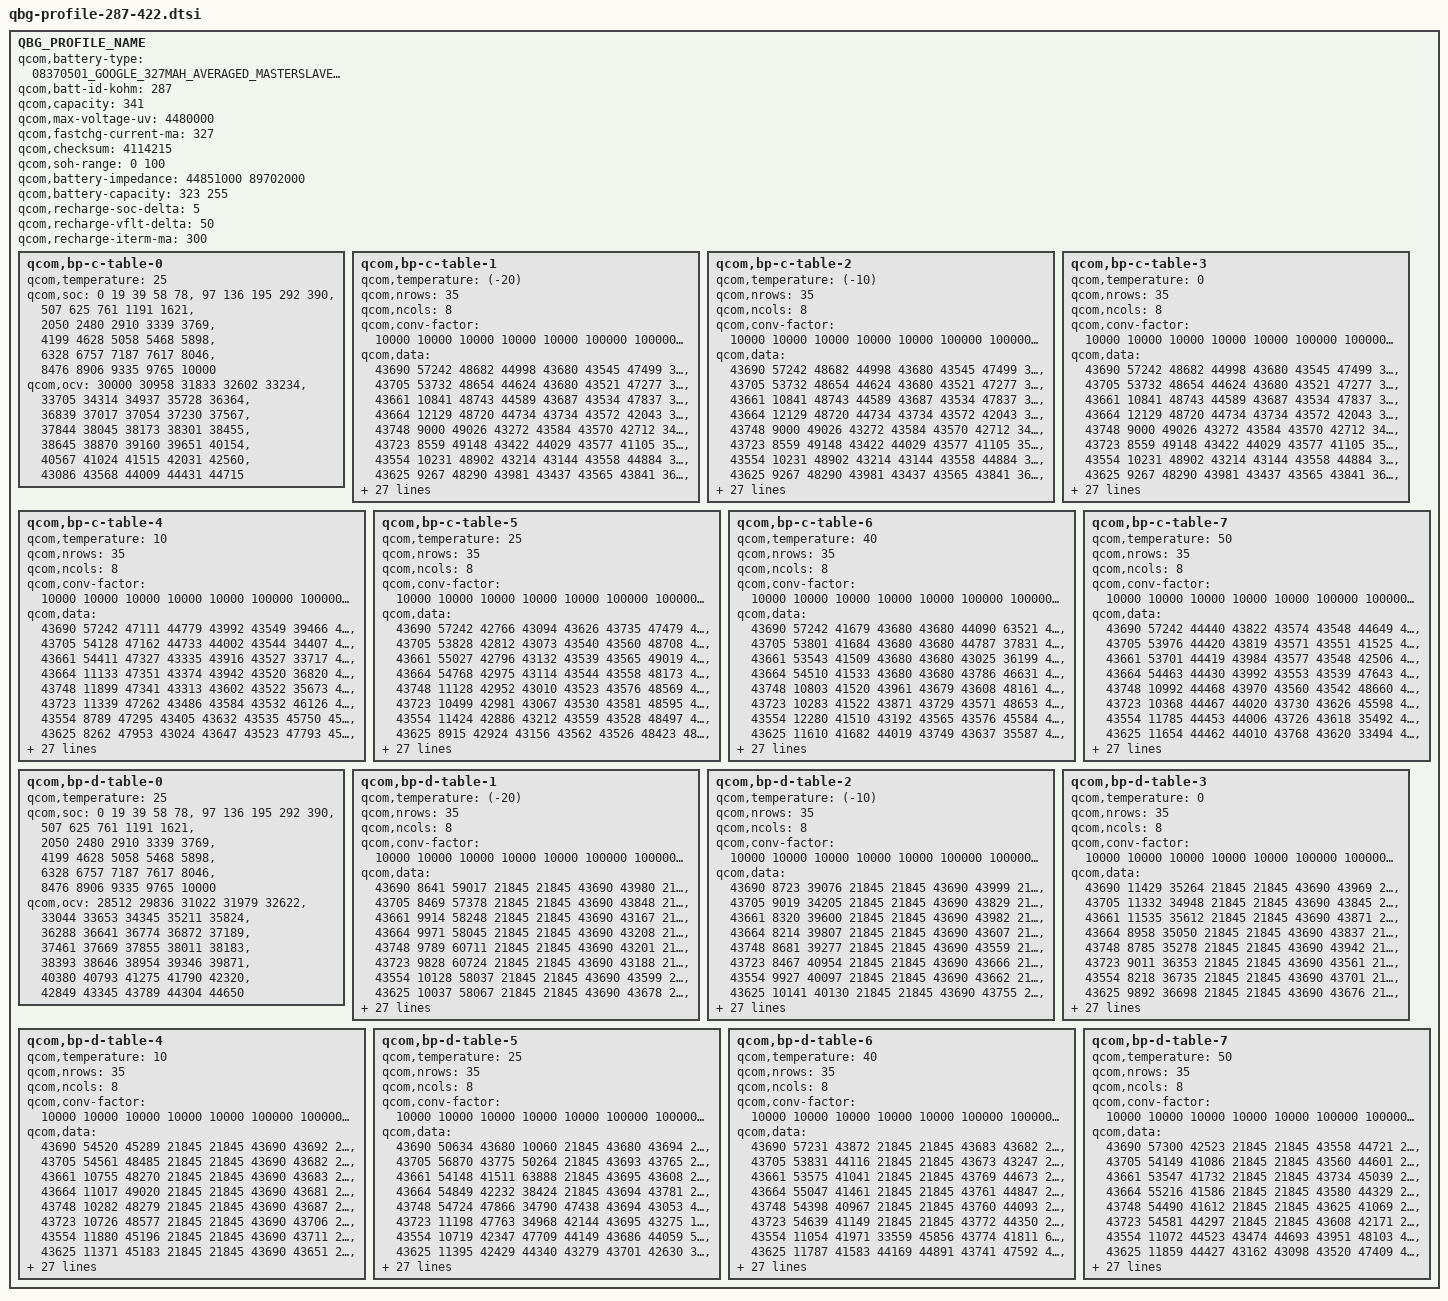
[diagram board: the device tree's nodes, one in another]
/*QBG Profiling Rev. 2.8*/

QBG_PROFILE_NAME {
	qcom,battery-type = "08370501_GOOGLE_327MAH_AVERAGED_MASTERSLAVE_MAR23RD2026";
	qcom,batt-id-kohm = <287>;
	qcom,capacity = <341>;
	qcom,max-voltage-uv = <4480000>;
	qcom,fastchg-current-ma = <327>;
	qcom,checksum = <4114215>; /*@5, 0.005V, 4% */
	qcom,soh-range = <0 100>;
	qcom,battery-impedance = <44851000 89702000>; /*Nominal_Impedance in 10nohm @ SOC 50% 25C* 0:fresh cell, 1: aged cell*/
	qcom,battery-capacity = <323 255>; /*Nominal_Capacity in mAh. 0: fresh cell, 1:aged cell*/ 
	qcom,recharge-soc-delta =<5>; /*SOC delta (in percent) dropped from EOC SOC to enable recharge*/ 
	qcom,recharge-vflt-delta =<50>; /*vfloat delta (in mV) dropped from regular vfloat in recharge*/ 
	qcom,recharge-iterm-ma = <300>; /*termination current (in mA) in recharge*/ 

	qcom,bp-c-table-0 {
		qcom,temperature = <25>;
		qcom,soc = <    0    19    39    58    78>,
			<   97   136   195   292   390>,
			<  507   625   761  1191  1621>,
			< 2050  2480  2910  3339  3769>,
			< 4199  4628  5058  5468  5898>,
			< 6328  6757  7187  7617  8046>,
			< 8476  8906  9335  9765 10000>;
		qcom,ocv = <30000 30958 31833 32602 33234>,
			<33705 34314 34937 35728 36364>,
			<36839 37017 37054 37230 37567>,
			<37844 38045 38173 38301 38455>,
			<38645 38870 39160 39651 40154>,
			<40567 41024 41515 42031 42560>,
			<43086 43568 44009 44431 44715>;
	};
	qcom,bp-c-table-1 {
		qcom,temperature = <(-20)>;
		qcom,nrows = <35>;
		qcom,ncols = <8>;
		qcom,conv-factor = <10000 10000 10000 10000 10000 100000 100000 10000>;
		qcom,data = <43690 57242 48682 44998 43680 43545 47499 34993>,
			<43705 53732 48654 44624 43680 43521 47277 34964>,
			<43661 10841 48743 44589 43687 43534 47837 35035>,
			<43664 12129 48720 44734 43734 43572 42043 34821>,
			<43748  9000 49026 43272 43584 43570 42712 34911>,
			<43723  8559 49148 43422 44029 43577 41105 35220>,
			<43554 10231 48902 43214 43144 43558 44884 35169>,
			<43625  9267 48290 43981 43437 43565 43841 36606>,
			<43918 15018 48273 43770 43281 43578 43938 36571>,
			<43820 15047 48276 43771 43363 43579 43950 36603>,
			<43857 14861 48346 43526 43464 43570 44004 36482>,
			<43227 14961 48172 43625 43313 43555 44024 36458>,
			<43091 15247 48141 43632 43301 43556 43974 36774>,
			<44557 14546 48613 43852 43487 43558 44737 36327>,
			<44287 14642 48447 44503 44030 43556 35351 32831>,
			<41640 16081 48567 41600 43883 43582 45521 32994>,
			<41754 16303 48203 41530 43232 43583 48342 32925>,
			<41460 16351 48562 41550 43056 43559 48737 33163>,
			<42913 16216 48588 41956 43127 43567 48696 34498>,
			<42003 15423 48401 41750 43454 43733 48825 34671>,
			<47821 15814 45708 41103 43496 43731 47358 34192>,
			<47294 13014 45676 41175 43482 43736 42295 39448>,
			<47464 13153 45977 41013 43293 43718 41048 39076>,
			<49142 12680 45220 41024 44687 43724 41508 39254>,
			<48544 13832 45068 41410 44545 43720 44530 40138>,
			<45586 13460 45565 41287 45041 43764 44284 37786>,
			<45263 13660 46845 42714 44232 43761 45053 38422>,
			<46777  2921 47061 42571 41645 43760 44737 60365>,
			<46955  2307 46182 42938 41022 43762 43463 60831>,
			<46532  3892 35483 42883 42217 43763 43036 58588>,
			<35766  3376 35782 42970 47539 43761 43165 65017>,
			<34912   979 34848 42203 46029 43767 43858 51436>,
			<36573   389 35265 42099 36404 43761 43881 55353>,
			<35983  1657 36510 42577 34765 43762 44021 55119>,
			<36282  1890 36769 41551 33519 43732 43590 54155>;
	};
	qcom,bp-c-table-2 {
		qcom,temperature = <(-10)>;
		qcom,nrows = <35>;
		qcom,ncols = <8>;
		qcom,conv-factor = <10000 10000 10000 10000 10000 100000 100000 10000>;
		qcom,data = <43690 57242 48682 44998 43680 43545 47499 34993>,
			<43705 53732 48654 44624 43680 43521 47277 34964>,
			<43661 10841 48743 44589 43687 43534 47837 35035>,
			<43664 12129 48720 44734 43734 43572 42043 34821>,
			<43748  9000 49026 43272 43584 43570 42712 34911>,
			<43723  8559 49148 43422 44029 43577 41105 35220>,
			<43554 10231 48902 43214 43144 43558 44884 35169>,
			<43625  9267 48290 43981 43437 43565 43841 36606>,
			<43918 15018 48273 43770 43281 43578 43938 36571>,
			<43820 15047 48276 43771 43363 43579 43950 36603>,
			<43857 14861 48346 43526 43464 43570 44004 36482>,
			<43227 14961 48172 43625 43313 43555 44024 36458>,
			<43091 15247 48141 43632 43301 43556 43974 36774>,
			<44557 14546 48613 43852 43487 43558 44737 36327>,
			<44287 14642 48447 44503 44030 43556 35351 32831>,
			<41640 16081 48567 41600 43883 43582 45521 32994>,
			<41754 16303 48203 41530 43232 43583 48342 32925>,
			<41460 16351 48562 41550 43056 43559 48737 33163>,
			<42913 16216 48588 41956 43127 43567 48696 34498>,
			<42003 15423 48401 41750 43454 43733 48825 34671>,
			<47821 15814 45708 41103 43496 43731 47358 34192>,
			<47294 13014 45676 41175 43482 43736 42295 39448>,
			<47464 13153 45977 41013 43293 43718 41048 39076>,
			<49142 12680 45220 41024 44687 43724 41508 39254>,
			<48544 13832 45068 41410 44545 43720 44530 40138>,
			<45586 13460 45565 41287 45041 43764 44284 37786>,
			<45263 13660 46845 42714 44232 43761 45053 38422>,
			<46777  2921 47061 42571 41645 43760 44737 60365>,
			<46955  2307 46182 42938 41022 43762 43463 60831>,
			<46532  3892 35483 42883 42217 43763 43036 58588>,
			<35766  3376 35782 42970 47539 43761 43165 65017>,
			<34912   979 34848 42203 46029 43767 43858 51436>,
			<36573   389 35265 42099 36404 43761 43881 55353>,
			<35983  1657 36510 42577 34765 43762 44021 55119>,
			<36282  1890 36769 41551 33519 43732 43590 54155>;
	};
	qcom,bp-c-table-3 {
		qcom,temperature = <0>;
		qcom,nrows = <35>;
		qcom,ncols = <8>;
		qcom,conv-factor = <10000 10000 10000 10000 10000 100000 100000 10000>;
		qcom,data = <43690 57242 48682 44998 43680 43545 47499 34993>,
			<43705 53732 48654 44624 43680 43521 47277 34964>,
			<43661 10841 48743 44589 43687 43534 47837 35035>,
			<43664 12129 48720 44734 43734 43572 42043 34821>,
			<43748  9000 49026 43272 43584 43570 42712 34911>,
			<43723  8559 49148 43422 44029 43577 41105 35220>,
			<43554 10231 48902 43214 43144 43558 44884 35169>,
			<43625  9267 48290 43981 43437 43565 43841 36606>,
			<43918 15018 48273 43770 43281 43578 43938 36571>,
			<43820 15047 48276 43771 43363 43579 43950 36603>,
			<43857 14861 48346 43526 43464 43570 44004 36482>,
			<43227 14961 48172 43625 43313 43555 44024 36458>,
			<43091 15247 48141 43632 43301 43556 43974 36774>,
			<44557 14546 48613 43852 43487 43558 44737 36327>,
			<44287 14642 48447 44503 44030 43556 35351 32831>,
			<41640 16081 48567 41600 43883 43582 45521 32994>,
			<41754 16303 48203 41530 43232 43583 48342 32925>,
			<41460 16351 48562 41550 43056 43559 48737 33163>,
			<42913 16216 48588 41956 43127 43567 48696 34498>,
			<42003 15423 48401 41750 43454 43733 48825 34671>,
			<47821 15814 45708 41103 43496 43731 47358 34192>,
			<47294 13014 45676 41175 43482 43736 42295 39448>,
			<47464 13153 45977 41013 43293 43718 41048 39076>,
			<49142 12680 45220 41024 44687 43724 41508 39254>,
			<48544 13832 45068 41410 44545 43720 44530 40138>,
			<45586 13460 45565 41287 45041 43764 44284 37786>,
			<45263 13660 46845 42714 44232 43761 45053 38422>,
			<46777  2921 47061 42571 41645 43760 44737 60365>,
			<46955  2307 46182 42938 41022 43762 43463 60831>,
			<46532  3892 35483 42883 42217 43763 43036 58588>,
			<35766  3376 35782 42970 47539 43761 43165 65017>,
			<34912   979 34848 42203 46029 43767 43858 51436>,
			<36573   389 35265 42099 36404 43761 43881 55353>,
			<35983  1657 36510 42577 34765 43762 44021 55119>,
			<36282  1890 36769 41551 33519 43732 43590 54155>;
	};
	qcom,bp-c-table-4 {
		qcom,temperature = <10>;
		qcom,nrows = <35>;
		qcom,ncols = <8>;
		qcom,conv-factor = <10000 10000 10000 10000 10000 100000 100000 10000>;
		qcom,data = <43690 57242 47111 44779 43992 43549 39466 46997>,
			<43705 54128 47162 44733 44002 43544 34407 46663>,
			<43661 54411 47327 43335 43916 43527 33717 46640>,
			<43664 11133 47351 43374 43942 43520 36820 46819>,
			<43748 11899 47341 43313 43602 43522 35673 45392>,
			<43723 11339 47262 43486 43584 43532 46126 45316>,
			<43554  8789 47295 43405 43632 43535 45750 45450>,
			<43625  8262 47953 43024 43647 43523 47793 45273>,
			<43918 10027 47267 43198 43955 43542 44035 45853>,
			<43820  9718 47994 43633 43161 43585 43798 46072>,
			<43857 15090 47878 43947 43863 43589 43843 45993>,
			<43227 14896 47881 43610 43181 43584 43850 45666>,
			<43091 14950 47921 44004 43778 43587 43314 45598>,
			<44557 15212 47925 43484 43541 43533 46657 45909>,
			<44287 14783 48036 44643 43598 43572 36433 45119>,
			<41640 16039 47841 45028 43938 43521 36309 45231>,
			<41754 15877 42265 44851 43928 43536 36643 45877>,
			<41460 16310 42255 44831 44023 43549 35212 45925>,
			<42913 16179 42269 44923 43818 43526 35806 45215>,
			<42003 15515 42305 44194 43787 43534 35253 45160>,
			<47821 15442 47781 44267 43806 43572 36065 45536>,
			<47294 12989 47841 44229 43780 43581 35169 45315>,
			<47464 13118 47651 44253 43807 43558 45791 46766>,
			<49142 12684 47724 44247 43847 43563 42609 46644>,
			<48544 13934 48023 44138 43202 43730 41583 46924>,
			<45586 13530 47879 44468 43099 43736 44127 46546>,
			<45263  2707 47349 44335 43316 43713 44833 35836>,
			<46777  2227 47176 41654 44789 43715 44617 35123>,
			<46955  3769 47395 41501 45004 43714 44786 35987>,
			<46532  3210 48872 41969 44148 43712 43360 33583>,
			<35766   652 48709 41118 41859 43712 43516 34645>,
			<34912   161 48945 40999 42936 43712 43123 40612>,
			<36573   366 48334 41209 49036 43712 43158 38687>,
			<35983  1996 48523 44369 45766 43766 43862 60290>,
			<36282  1219 45618 44665 48409 43770 43603 38187>;
	};
	qcom,bp-c-table-5 {
		qcom,temperature = <25>;
		qcom,nrows = <35>;
		qcom,ncols = <8>;
		qcom,conv-factor = <10000 10000 10000 10000 10000 100000 100000 10000>;
		qcom,data = <43690 57242 42766 43094 43626 43735 47479 47368>,
			<43705 53828 42812 43073 43540 43560 48708 47564>,
			<43661 55027 42796 43132 43539 43565 49019 47501>,
			<43664 54768 42975 43114 43544 43558 48173 47180>,
			<43748 11128 42952 43010 43523 43576 48569 47118>,
			<43723 10499 42981 43067 43530 43581 48595 47310>,
			<43554 11424 42886 43212 43559 43528 48497 47941>,
			<43625  8915 42924 43156 43562 43526 48423 48095>,
			<43918  8506 42613 43150 43562 43550 48699 48063>,
			<43820  9382 42524 43868 43552 43541 47741 47639>,
			<43857  9549 42547 43855 43724 43631 45727 47857>,
			<43227 14899 42708 44006 43593 43632 42941 47806>,
			<43091 14868 42690 43863 43767 43626 46695 47745>,
			<44557 15300 42728 43011 43550 43575 45576 48011>,
			<44287 14357 41308 43399 43588 43559 45552 47917>,
			<41640 14718 41227 43509 43936 43558 45505 48085>,
			<41754 15927 41458 43474 43936 43553 45948 48101>,
			<41460 16311 41370 43473 43909 43552 48911 48099>,
			<42913 16183 41389 43476 44019 43554 47124 48099>,
			<42003 15517 41038 43307 43819 43555 47255 48126>,
			<47821 15455 40981 43316 43789 43567 49108 48069>,
			<47294 15740 40978 43289 43783 43565 45356 47912>,
			<47464 12882 40973 43346 43990 43577 40329 47912>,
			<49142 12361 41010 43265 43924 43559 46364 47694>,
			<48544 13936 41006 43477 43920 43561 41153 47624>,
			<45586 13533 41180 43360 43978 43562 41909 48043>,
			<45263  2794 41168 44701 43785 43728 44346 47980>,
			<46777  2177 41012 44604 43169 43740 44165 47123>,
			<46955  3717 41073 44939 43230 43731 44819 47442>,
			<46532  3306 41355 44905 43424 43741 44832 48931>,
			<35766   740 41435 44889 44694 43737 44787 48627>,
			<34912   154 41327 44214 44201 43740 43292 45841>,
			<36573   323 42629 44882 41199 43733 43087 46282>,
			<35983  1829 42525 44749 44385 43740 43477 45500>,
			<36282  1025 42826 43450 42987 43740 44020 35336>;
	};
	qcom,bp-c-table-6 {
		qcom,temperature = <40>;
		qcom,nrows = <35>;
		qcom,ncols = <8>;
		qcom,conv-factor = <10000 10000 10000 10000 10000 100000 100000 10000>;
		qcom,data = <43690 57242 41679 43680 43680 44090 63521 43680>,
			<43705 53801 41684 43680 43680 44787 37831 43680>,
			<43661 53543 41509 43680 43680 43025 36199 43250>,
			<43664 54510 41533 43680 43680 43786 46631 44442>,
			<43748 10803 41520 43961 43679 43608 48161 41118>,
			<43723 10283 41522 43871 43729 43571 48653 41327>,
			<43554 12280 41510 43192 43565 43576 45584 42668>,
			<43625 11610 41682 44019 43749 43637 35587 41057>,
			<43918  8272 41665 43798 43760 43538 36435 41364>,
			<43820 10222 41727 44022 43771 43614 35387 40975>,
			<43857  9699 41696 44008 43744 43589 46584 41178>,
			<43227 15080 41707 43976 43768 43616 48499 40960>,
			<43091 15056 41630 43960 43755 43951 45414 41098>,
			<44557 15273 41608 43790 43547 43539 41996 41450>,
			<44287 14566 41645 43893 43638 43524 47810 41277>,
			<41640 14836 44359 43862 43589 43526 47178 41223>,
			<41754 16025 44408 43192 43639 43523 45752 41271>,
			<41460 15994 44310 43170 43639 43520 48056 41262>,
			<42913 16334 44303 43183 43961 43521 42697 41271>,
			<42003 15545 44344 43884 43816 43527 44502 41237>,
			<47821 15473 44329 43902 43776 43523 41584 41282>,
			<47294 15724 44509 43857 43777 43533 42645 42660>,
			<47464 12889 44487 43245 43993 43532 45777 42657>,
			<49142 12310 44492 43149 43963 43535 48121 41272>,
			<48544 13876 44488 43175 43613 43534 41870 41456>,
			<45586 13550 44533 43149 43936 43575 44300 41252>,
			<45263  2744 44529 43249 43910 43582 44042 41287>,
			<46777  2222 44529 43016 44029 43556 44886 42701>,
			<46955  3744 44535 43392 43812 43564 44204 42908>,
			<46532  3252 44487 43305 43871 43563 45014 42148>,
			<35766   647 44320 43269 43065 43733 44642 42065>,
			<34912   164 44288 43348 43507 43564 44671 47748>,
			<36573   355 44410 43329 44953 43576 43356 47280>,
			<35983  1830 41661 43008 43265 43576 44690 42448>,
			<36282  1120 41856 43259 44366 43540 43820 48681>;
	};
	qcom,bp-c-table-7 {
		qcom,temperature = <50>;
		qcom,nrows = <35>;
		qcom,ncols = <8>;
		qcom,conv-factor = <10000 10000 10000 10000 10000 100000 100000 10000>;
		qcom,data = <43690 57242 44440 43822 43574 43548 44649 41742>,
			<43705 53976 44420 43819 43571 43551 41525 41735>,
			<43661 53701 44419 43984 43577 43548 42506 41729>,
			<43664 54463 44430 43992 43553 43539 47643 41737>,
			<43748 10992 44468 43970 43560 43542 48660 41790>,
			<43723 10368 44467 44020 43730 43626 45598 41768>,
			<43554 11785 44453 44006 43726 43618 35492 41974>,
			<43625 11654 44462 44010 43768 43620 33494 41879>,
			<43918  8444 44112 44000 43744 43620 39821 41886>,
			<43820  9741 44120 43923 43671 43639 37947 41902>,
			<43857  9318 44102 43965 43756 43589 36262 41591>,
			<43227  9558 44109 43594 43759 43607 48150 41527>,
			<43091 14999 44106 43599 43753 43615 45804 41525>,
			<44557 14876 44146 43916 43536 43639 41755 41934>,
			<44287 15188 44134 44030 43641 43641 42679 41740>,
			<41640 14759 44136 43973 43594 43642 48015 41836>,
			<41754 14658 44060 43975 43637 43622 47380 41751>,
			<41460 15884 44035 43981 43629 43616 42194 41788>,
			<42913 16355 44083 43823 43647 43622 42582 41757>,
			<42003 16213 44071 43959 43987 43632 44993 41804>,
			<47821 15460 44079 43906 43790 43640 44231 41150>,
			<47294 15720 44244 44000 43787 43616 41551 41116>,
			<47464 12893 44253 43833 43976 43629 47953 41089>,
			<49142 12394 44254 43985 43591 43618 42753 41734>,
			<48544 13886 44248 43982 43638 43628 44359 41774>,
			<45586 13461 44229 43997 43611 43540 44269 41752>,
			<45263  2721 44228 43777 43936 43547 44870 41124>,
			<46777  2896 44228 43840 43915 43534 44895 41182>,
			<46955  3752 44229 43242 43921 43571 44221 41028>,
			<46532  3250 44249 43010 43813 43557 44849 41232>,
			<35766   692 44245 43091 43892 43578 44163 42694>,
			<34912   174 44091 43436 43041 43580 45028 42885>,
			<36573   276 44045 43095 43292 43572 44586 42229>,
			<35983  1826 44133 43166 43069 43526 44994 42539>,
			<36282  1147 44313 43778 44523 43628 43790 47922>;
	};
	qcom,bp-d-table-0 {
		qcom,temperature = <25>;
		qcom,soc = <    0    19    39    58    78>,
			<   97   136   195   292   390>,
			<  507   625   761  1191  1621>,
			< 2050  2480  2910  3339  3769>,
			< 4199  4628  5058  5468  5898>,
			< 6328  6757  7187  7617  8046>,
			< 8476  8906  9335  9765 10000>;
		qcom,ocv = <28512 29836 31022 31979 32622>,
			<33044 33653 34345 35211 35824>,
			<36288 36641 36774 36872 37189>,
			<37461 37669 37855 38011 38183>,
			<38393 38646 38954 39346 39871>,
			<40380 40793 41275 41790 42320>,
			<42849 43345 43789 44304 44650>;
	};
	qcom,bp-d-table-1 {
		qcom,temperature = <(-20)>;
		qcom,nrows = <35>;
		qcom,ncols = <8>;
		qcom,conv-factor = <10000 10000 10000 10000 10000 100000 100000 10000>;
		qcom,data = <43690  8641 59017 21845 21845 43690 43980 21845>,
			<43705  8469 57378 21845 21845 43690 43848 21845>,
			<43661  9914 58248 21845 21845 43690 43167 21845>,
			<43664  9971 58045 21845 21845 43690 43208 21845>,
			<43748  9789 60711 21845 21845 43690 43201 21845>,
			<43723  9828 60724 21845 21845 43690 43188 21845>,
			<43554 10128 58037 21845 21845 43690 43599 21845>,
			<43625 10037 58067 21845 21845 43690 43678 21845>,
			<43918 10067 58272 21845 16615 43690 43745 21845>,
			<43820  9447 57497 21845  9431 43690 43726 21845>,
			<43857  9219 60511 21845 62071 43690 43554 21845>,
			<43227  9639 61149 21845 36970 43690 43635 21845>,
			<43091  9669 61017 21845 33785 43690 43923 21845>,
			<44557 15068 38506 29311 34832 43691 43008 21845>,
			<44287 15244 37618 10986 46313 43691 43433 21845>,
			<41640 15135 40840 64925 45679 43688 43448 21845>,
			<41754 14585 39053 38307 47550 43688 43327 20876>,
			<41460 14416 34167 39425 42396 43689 44687 32295>,
			<42913 14607 34571 35958 42734 43695 44595  7529>,
			<42003 16114 34336 46455 41792 43692 44974  2681>,
			<47821 16307 32859 45116 41602 43682 45029  9245>,
			<47294 16216 33485 48191 44101 43680 44856 10779>,
			<47464 15428 36236 47479 44193 43687 44207 56479>,
			<49142 12965 36042 47159 45033 43684 44485 50532>,
			<48544 13112 36614 48076 44639 43705 40979 49618>,
			<45586 12736 36700 47710 44945 43672 47647 49463>,
			<45263 14297 36678 47735 44913 43668 47190 50846>,
			<46777 13580 36715 47645 44081 43771 49086 51107>,
			<46955  2885 36708 47646 44435 43718 48279 50426>,
			<46532  3765 35994 48064 44316 43718 48955 50493>,
			<35766  3220 36827 47966 44353 43725 47614 55973>,
			<34912   764 36853 47141 44303 43765 47842 55947>,
			<36573   201 36668 47504 44050 43676 41395 50465>,
			<35983  1607 35976 47443 44989 43690 43318 50309>,
			<36282  1035 36074 48868 44792 43690 43690 50962>;
	};
	qcom,bp-d-table-2 {
		qcom,temperature = <(-10)>;
		qcom,nrows = <35>;
		qcom,ncols = <8>;
		qcom,conv-factor = <10000 10000 10000 10000 10000 100000 100000 10000>;
		qcom,data = <43690  8723 39076 21845 21845 43690 43999 21845>,
			<43705  9019 34205 21845 21845 43690 43829 21845>,
			<43661  8320 39600 21845 21845 43690 43982 21845>,
			<43664  8214 39807 21845 21845 43690 43607 21845>,
			<43748  8681 39277 21845 21845 43690 43559 21845>,
			<43723  8467 40954 21845 21845 43690 43666 21845>,
			<43554  9927 40097 21845 21845 43690 43662 21845>,
			<43625 10141 40130 21845 21845 43690 43755 21845>,
			<43918  9406 40809 21845 10376 43690 43732 21845>,
			<43820  9241 40606 21845 38137 43690 43610 21845>,
			<43857  9602 39888 21845 35554 43690 43979 21845>,
			<43227  9511 34217 32272 47389 43690 43860 21845>,
			<43091  9564 34330 49949 42915 43691 43093 21845>,
			<44557 14919 35950 36836 41736 43688 44971  4263>,
			<44287 15155 35031 45969 41532 43692 44913 12094>,
			<41640 14472 46373 47353 44266 43684 44034 52700>,
			<41754 14337 46083 42124 44547 43675 44295 61832>,
			<41460 14736 46131 42699 43271 43749 41510 65315>,
			<42913 14712 46091 41459 43444 43760 41496 64332>,
			<42003 15914 46188 40998 43117 43765 41586 58755>,
			<47821 16335 46161 41198 43017 43727 41426 59152>,
			<47294 15364 46494 40974 43014 43718 48917 59334>,
			<47464 12947 46171 41080 43302 43737 45945 59247>,
			<49142 13059 46191 41048 44728 43740 48332 59248>,
			<48544 12788 46148 41444 44546 43730 49061 58600>,
			<45586 14224 46169 41316 44950 43730 47467 58462>,
			<45263 13723 46167 42741 44830 43740 47340 58633>,
			<46777  2961 46508 42578 44204 43737 48040 64140>,
			<46955  2556 46177 42790 44264 43716 47759 64014>,
			<46532  4061 46179 42124 44079 43712 42351 64316>,
			<35766  3368 46518 42008 44059 43725 42372 63519>,
			<34912  1017 46116 42412 44279 43722 42988 63914>,
			<36573    84 46277 42015 44955 43775 40993 63534>,
			<35983  1932 46272 42761 43448 43759 44430 64438>,
			<36282  1050 46298 42922 43181 43670 44982 64223>;
	};
	qcom,bp-d-table-3 {
		qcom,temperature = <0>;
		qcom,nrows = <35>;
		qcom,ncols = <8>;
		qcom,conv-factor = <10000 10000 10000 10000 10000 100000 100000 10000>;
		qcom,data = <43690 11429 35264 21845 21845 43690 43969 21845>,
			<43705 11332 34948 21845 21845 43690 43845 21845>,
			<43661 11535 35612 21845 21845 43690 43871 21845>,
			<43664  8958 35050 21845 21845 43690 43837 21845>,
			<43748  8785 35278 21845 21845 43690 43942 21845>,
			<43723  9011 36353 21845 21845 43690 43561 21845>,
			<43554  8218 36735 21845 21845 43690 43701 21845>,
			<43625  9892 36698 21845 21845 43690 43676 21845>,
			<43918 10015 36626 21845 61974 43690 43523 21845>,
			<43820  9271 35119 21845 35404 43690 44028 21845>,
			<43857  9601 34942  3502 42128 43690 43159 21845>,
			<43227  9507 35412 38328 41709 43691 43508 21836>,
			<43091  9585 46229 45875 45035 43688 44619  3414>,
			<44557 14956 45473 41123 43206 43681 41909 65037>,
			<44287 15317 45988 41802 43105 43658 41968 57557>,
			<41640 14473 45607 41628 43214 43749 41259 60390>,
			<41754 14453 45572 44378 43160 43726 48867 38422>,
			<41460 14639 45667 44288 43189 43718 48302 37636>,
			<42913 16003 45676 44502 43191 43738 49025 40302>,
			<42003 15956 45678 44328 43242 43737 48325 40031>,
			<47821 15520 45657 44345 43035 43740 48336 39941>,
			<47294 15745 45984 44340 43428 43730 47312 39979>,
			<47464 13009 45925 44406 43458 43728 47714 39981>,
			<49142 13126 45984 41624 43375 43729 42294 39941>,
			<48544 12558 45695 41497 44778 43728 42109 40372>,
			<45586 14127 45644 41963 44562 43741 42859 40215>,
			<45263 13608 45990 41849 44989 43736 42709 37580>,
			<46777  2874 46001 41163 45042 43719 41276 37799>,
			<46955  2313 45695 41080 45021 43714 40980 37639>,
			<46532  3859 45570 41345 44846 43726 41193 36993>,
			<35766  3345 45616 41420 45012 43722 41837 37084>,
			<34912   831 45601 41278 45033 43767 41805 36962>,
			<36573   415 45605 41447 44748 43763 41839 36905>,
			<35983  1943 45579 41156 43117 43768 41876 37843>,
			<36282  1050 45569 41129 43860 43749 41564 37502>;
	};
	qcom,bp-d-table-4 {
		qcom,temperature = <10>;
		qcom,nrows = <35>;
		qcom,ncols = <8>;
		qcom,conv-factor = <10000 10000 10000 10000 10000 100000 100000 10000>;
		qcom,data = <43690 54520 45289 21845 21845 43690 43692 21845>,
			<43705 54561 48485 21845 21845 43690 43682 21845>,
			<43661 10755 48270 21845 21845 43690 43683 21845>,
			<43664 11017 49020 21845 21845 43690 43681 21845>,
			<43748 10282 48279 21845 21845 43690 43687 21845>,
			<43723 10726 48577 21845 21845 43690 43706 21845>,
			<43554 11880 45196 21845 21845 43690 43711 21845>,
			<43625 11371 45183 21845 21845 43690 43651 21845>,
			<43918  8989 45903 21845  8044 43690 43582 21845>,
			<43820  9907 45810 21432 36070 43690 43875 21845>,
			<43857  9385 48512 57959 41282 43691 43319 22120>,
			<43227  9643 48153 48637 44804 43688 44837 12734>,
			<43091  9683 49146 41868 43080 43692 41643 62636>,
			<44557 14984 48716 44961 44005 43745 42672 38955>,
			<44287 15320 47462 44874 43184 43767 48858 34011>,
			<41640 14535 47380 44803 43037 43718 47724 33648>,
			<41754 14777 47598 44841 43026 43743 42251 35844>,
			<41460 14653 47566 44995 43233 43728 42493 36413>,
			<42913 16021 47489 45008 43144 43735 47258 35122>,
			<42003 16306 47511 44844 43250 43732 47219 35201>,
			<47821 15530 47490 44832 43223 43732 47786 34914>,
			<47294 15783 47510 44852 43059 43562 42871 34854>,
			<47464 13051 47504 44922 43109 43562 42566 34818>,
			<49142 13162 47497 44210 43400 43733 42750 34902>,
			<48544 12590 47543 44079 43315 43732 42649 35098>,
			<45586 14121 47502 44426 44728 43732 42500 36377>,
			<45263 13630 47548 44297 44749 43735 42605 36824>,
			<46777  2878 47536 44411 44599 43742 41123 36730>,
			<46955  2359 47539 44364 44650 43712 41705 35995>,
			<46532  3846 47523 41610 44584 43719 41636 35900>,
			<35766  3347 47522 41700 44763 43724 41600 36279>,
			<34912   817 47526 41667 44696 43715 41914 36131>,
			<36573   490 47517 41607 43279 43714 41962 36152>,
			<35983  1943 47417 44511 43107 43767 41673 36290>,
			<36282  1036 47475 44476 43237 43768 44470 36245>;
	};
	qcom,bp-d-table-5 {
		qcom,temperature = <25>;
		qcom,nrows = <35>;
		qcom,ncols = <8>;
		qcom,conv-factor = <10000 10000 10000 10000 10000 100000 100000 10000>;
		qcom,data = <43690 50634 43680 10060 21845 43680 43694 21845>,
			<43705 56870 43775 50264 21845 43693 43765 21845>,
			<43661 54148 41511 63888 21845 43695 43608 21845>,
			<43664 54849 42232 38424 21845 43694 43781 21845>,
			<43748 54724 47866 34790 47438 43694 43053  4048>,
			<43723 11198 47763 34968 42144 43695 43275 11511>,
			<43554 10719 42347 47709 44149 43686 44059 51371>,
			<43625 11395 42429 44340 43279 43701 42630 38253>,
			<43918  8993 42189 44597 43033 43771 48335 34961>,
			<43820  8538 42122 44771 43124 43764 46694 47066>,
			<43857 10090 42825 43332 43893 43714 48438 45229>,
			<43227  9611 42757 43287 43785 43737 41284 48397>,
			<43091  9484 42996 43294 44019 43743 42960 48329>,
			<44557 15010 42575 43124 43521 43564 48825 47519>,
			<44287 15343 42707 43405 43812 43733 41324 47413>,
			<41640 14591 41296 43493 43894 43566 42569 47594>,
			<41754 14735 41236 43514 43143 43554 42922 47543>,
			<41460 14709 41230 43304 43242 43552 48093 47490>,
			<42913 16081 41253 43507 43246 43552 42796 47200>,
			<42003 16269 41425 43411 43190 43558 40986 47351>,
			<47821 16211 41409 43412 43855 43553 41102 47265>,
			<47294 15452 41465 43490 43880 43553 41010 47974>,
			<47464 12928 41363 43509 43878 43552 41423 47992>,
			<49142 13080 41398 43293 43187 43578 42377 47354>,
			<48544 12565 41046 44697 43454 43583 47873 47384>,
			<45586 14102 41078 44783 43289 43557 42265 48865>,
			<45263 13811 41064 44715 43474 43561 41670 47361>,
			<46777  2961 40988 43344 43398 43563 44144 47615>,
			<46955  2452 40983 44725 43119 43560 44153 47490>,
			<46532  4090 41065 44764 43145 43552 41597 47173>,
			<35766  3531 41080 44758 43878 43553 41005 47211>,
			<34912  1019 41044 44789 43881 43555 40977 47125>,
			<36573   423 41345 44685 43797 43565 41087 47125>,
			<35983  1978 41446 43336 43792 43554 41054 47127>,
			<36282  1216 41456 43282 43805 43555 41388 47121>;
	};
	qcom,bp-d-table-6 {
		qcom,temperature = <40>;
		qcom,nrows = <35>;
		qcom,ncols = <8>;
		qcom,conv-factor = <10000 10000 10000 10000 10000 100000 100000 10000>;
		qcom,data = <43690 57231 43872 21845 21845 43683 43682 21845>,
			<43705 53831 44116 21845 21845 43673 43247 21845>,
			<43661 53575 41041 21845 21845 43769 44673 21845>,
			<43664 55047 41461 21845 21845 43761 44847 21845>,
			<43748 54398 40967 21845 21845 43760 44093 21845>,
			<43723 54639 41149 21845 21845 43772 44350 21845>,
			<43554 11054 41971 33559 45856 43774 41811 62378>,
			<43625 11787 41583 44169 44891 43741 47592 48565>,
			<43918  8900 41685 43066 43470 43554 45166 42266>,
			<43820  8261 41718 43250 43402 43557 46552 42054>,
			<43857  9804 41707 43245 43172 43580 35390 42814>,
			<43227  9260 41627 43263 43935 43570 45086 42503>,
			<43091  9533 41612 43231 43963 43581 42130 42548>,
			<44557 15023 41632 43837 43553 43521 47881 41386>,
			<44287 15264 44366 43899 43941 43525 42666 41267>,
			<41640 14518 44395 43866 44005 43525 42625 41337>,
			<41754 14766 44319 43843 43792 43547 41456 42636>,
			<41460 14681 44293 43871 43257 43549 41937 42605>,
			<42913 15874 44295 43238 43179 43539 41393 42602>,
			<42003 16333 44343 43247 43877 43550 41069 42539>,
			<47821 15509 44347 43137 43838 43547 40999 42632>,
			<47294 15766 44332 43138 44002 43546 42646 41324>,
			<47464 12998 44503 43199 44004 43524 41220 41239>,
			<49142 12477 44505 43164 43860 43521 42989 42709>,
			<48544 13966 44493 43224 43093 43523 42446 42776>,
			<45586 14203 44491 43164 43397 43534 44430 42758>,
			<45263 13580 44533 43070 43021 43535 44474 42791>,
			<46777  2855 44488 43094 43848 43524 41516 42986>,
			<46955  2362 44480 43392 44028 43534 40987 42590>,
			<46532  3849 44498 43437 43907 43576 41394 42522>,
			<35766  3333 44320 43109 43954 43576 41218 42711>,
			<34912   828 44338 43049 43958 43570 41436 42640>,
			<36573   486 44294 43257 43910 43573 41421 42626>,
			<35983  1945 44391 43242 44015 43533 42671 42645>,
			<36282  1220 44362 43244 44030 43526 42683 42690>;
	};
	qcom,bp-d-table-7 {
		qcom,temperature = <50>;
		qcom,nrows = <35>;
		qcom,ncols = <8>;
		qcom,conv-factor = <10000 10000 10000 10000 10000 100000 100000 10000>;
		qcom,data = <43690 57300 42523 21845 21845 43558 44721 21845>,
			<43705 54149 41086 21845 21845 43560 44601 21845>,
			<43661 53547 41732 21845 21845 43734 45039 21845>,
			<43664 55216 41586 21845 21845 43580 44329 21845>,
			<43748 54490 41612 21845 21845 43625 41069 21845>,
			<43723 54581 44297 21845 21845 43608 42171 21845>,
			<43554 11072 44523 43474 44693 43951 48103 47817>,
			<43625 11859 44427 43162 43098 43520 47409 42980>,
			<43918  8757 44116 43903 43046 43573 45216 42646>,
			<43820  8629 44109 43796 43086 43533 46289 42743>,
			<43857  9817 44153 43802 43868 43527 35738 41449>,
			<43227  9430 44128 43881 43942 43527 46489 41166>,
			<43091  9685 44142 43170 43646 43535 42365 41177>,
			<44557  9544 44061 43914 43731 43643 48780 41897>,
			<44287 14913 44047 43818 43618 43640 47663 41742>,
			<41640 15199 44089 43996 43960 43634 41331 41828>,
			<41754 14453 44068 43969 43977 43595 41320 41121>,
			<41460 14668 44065 43801 43843 43584 41800 41073>,
			<42913 15900 44076 43878 43183 43593 41930 41382>,
			<42003 16348 44244 43900 43792 43637 41786 41070>,
			<47821 15586 44242 43875 44025 43632 41138 41191>,
			<47294 15850 44248 43783 43951 43641 42750 41842>,
			<47464 13022 44231 43824 43937 43640 42905 41851>,
			<49142 12466 44225 43784 43873 43642 42719 41010>,
			<48544 14002 44237 43878 43037 43617 41823 41223>,
			<45586 14179 44277 43196 43201 43640 44391 41240>,
			<45263 13601 44276 43015 43985 43599 40985 41408>,
			<46777  3033 44234 43035 43957 43525 41458 41404>,
			<46955  2524 44232 43060 43620 43529 42342 40981>,
			<46532  3875 44224 43214 43546 43528 47297 41156>,
			<35766  3390 44250 43150 43526 43533 47219 41088>,
			<34912   977 44246 43853 43550 43545 47956 41817>,
			<36573   409 44070 43800 43634 43624 42393 41797>,
			<35983  1931 44042 43821 43913 43642 41116 41144>,
			<36282  1226 44038 43998 44015 43634 44295 41194>;
	};
};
